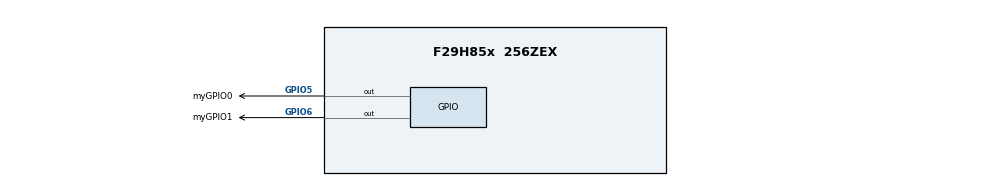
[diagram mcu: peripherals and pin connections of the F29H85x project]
/**
 * @cliArgs --device "F29H85x" --package "256ZEX" --part "F29H85x_256ZEX" --context "CPU1" --product "MCU_SDK_F29H85x@1.02.02.00"
 * @versions {"tool":"1.25.0+4237"}
 */

    
const divider15       = system.clockTree["PLL_REFDIV"];
divider15.divideValue = 1;

const multiplier1         = system.clockTree["PLL_IMULT"];
multiplier1.multiplyValue = 40;

const mux7       = system.clockTree["OSCCLKSRCSEL"];
mux7.inputSelect = "INTOSC2";

/**
 * Import the modules used in this configuration.
 */
const epwm             = scripting.addModule("/driverlib/epwm.js", {}, false);
const epwm1            = epwm.addInstance();
const gpio             = scripting.addModule("/driverlib/gpio.js", {}, false);
const gpio1            = gpio.addInstance();
const gpio2            = gpio.addInstance();
const inputxbar_input  = scripting.addModule("/driverlib/inputxbar_input.js", {}, false);
const inputxbar_input1 = inputxbar_input.addInstance();
const inputxbar_input2 = inputxbar_input.addInstance();
const inputxbar_input3 = inputxbar_input.addInstance();
const inputxbar_input4 = inputxbar_input.addInstance();

/**
 * Write custom configuration values to the imported modules.
 */
epwm1.$name                                                    = "myEPWM0";
epwm1.epwmTimebase_syncOutPulseMode                            = ["EPWM_SYNC_OUT_PULSE_ON_CNTR_ZERO"];
epwm1.epwmTimebase_hsClockDiv                                  = "EPWM_HSCLOCK_DIVIDER_1";
epwm1.epwmActionQualifier_EPWM_AQ_OUTPUT_A_ON_TIMEBASE_ZERO    = "EPWM_AQ_OUTPUT_HIGH";
epwm1.epwmActionQualifier_EPWM_AQ_OUTPUT_A_ON_TIMEBASE_UP_CMPA = "EPWM_AQ_OUTPUT_LOW";
epwm1.epwmActionQualifier_EPWM_AQ_OUTPUT_B_ON_TIMEBASE_UP_CMPA = "EPWM_AQ_OUTPUT_HIGH";
epwm1.epwmActionQualifier_EPWM_AQ_OUTPUT_B_ON_TIMEBASE_ZERO    = "EPWM_AQ_OUTPUT_LOW";
epwm1.epwmDeadband_polarityFED                                 = "EPWM_DB_POLARITY_ACTIVE_LOW";
epwm1.epwmDeadband_enableRED                                   = true;
epwm1.epwmDeadband_enableFED                                   = true;
epwm1.epwmDeadband_redShadowMode                               = true;
epwm1.epwmDeadband_fedShadowMode                               = true;
epwm1.epwmDeadband_controlShadowMode                           = true;
epwm1.epwmDeadband_delayRED                                    = 10;
epwm1.epwmDeadband_delayFED                                    = 10;
epwm1.epwmCounterCompare_cmpB                                  = 125;
epwm1.epwmTimebase_period                                      = 1000;
epwm1.epwmCounterCompare_cmpA                                  = 500;
epwm1.epwm.$assign                                             = "EPWM1";
epwm1.periphClock.$name                                        = "driverlib_perClock0";
epwm1.periphConfig.$name                                       = "driverlib_perConfig0";

gpio1.$name           = "myGPIO0";
gpio1.direction       = "GPIO_DIR_MODE_OUT";
gpio1.gpioPin.$assign = "GPIO5";

gpio2.$name           = "myGPIO1";
gpio2.direction       = "GPIO_DIR_MODE_OUT";
gpio2.gpioPin.$assign = "GPIO6";

inputxbar_input1.$name          = "sig1";
inputxbar_input1.inputxbarInput = "XBAR_INPUT33";
inputxbar_input1.inputxbarGpio  = "GPIO0";

inputxbar_input2.$name          = "sig2";
inputxbar_input2.inputxbarInput = "XBAR_INPUT34";
inputxbar_input2.inputxbarGpio  = "GPIO1";

inputxbar_input3.$name          = "trig1";
inputxbar_input3.inputxbarInput = "XBAR_INPUT44";
inputxbar_input3.inputxbarGpio  = "GPIO5";

inputxbar_input4.$name          = "trig2";
inputxbar_input4.inputxbarGpio  = "GPIO6";
inputxbar_input4.inputxbarInput = "XBAR_INPUT38";

/**
 * Pinmux solution for unlocked pins/peripherals. This ensures that minor changes to the automatic solver in a future
 * version of the tool will not impact the pinmux you originally saw.  These lines can be completely deleted in order to
 * re-solve from scratch.
 */
epwm1.epwm.epwm_aPin.$suggestSolution = "GPIO0";
epwm1.epwm.epwm_bPin.$suggestSolution = "GPIO1";
